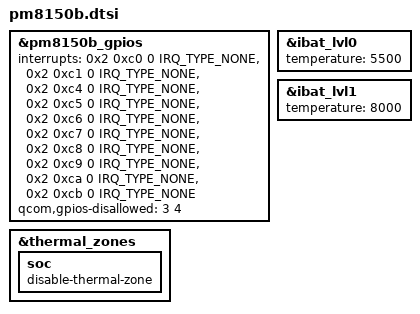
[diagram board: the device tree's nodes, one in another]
&pm8150b_gpios {
	interrupts = <0x2 0xc0 0 IRQ_TYPE_NONE>,
			<0x2 0xc1 0 IRQ_TYPE_NONE>,
			<0x2 0xc4 0 IRQ_TYPE_NONE>,
			<0x2 0xc5 0 IRQ_TYPE_NONE>,
			<0x2 0xc6 0 IRQ_TYPE_NONE>,
			<0x2 0xc7 0 IRQ_TYPE_NONE>,
			<0x2 0xc8 0 IRQ_TYPE_NONE>,
			<0x2 0xc9 0 IRQ_TYPE_NONE>,
			<0x2 0xca 0 IRQ_TYPE_NONE>,
			<0x2 0xcb 0 IRQ_TYPE_NONE>;
	interrupt-names = "pm8150b_gpio1", "pm8150b_gpio2",
			"pm8150b_gpio5", "pm8150b_gpio6",
			"pm8150b_gpio7",
			"pm8150b_gpio8", "pm8150b_gpio9",
			"pm8150b_gpio10", "pm8150b_gpio11",
			"pm8150b_gpio12";
	qcom,gpios-disallowed = <3 4>;
};

&ibat_lvl0 {
	temperature = <5500>;
};

&ibat_lvl1 {
	temperature = <8000>;
};

&thermal_zones {
	soc {
		disable-thermal-zone;
	};
};
